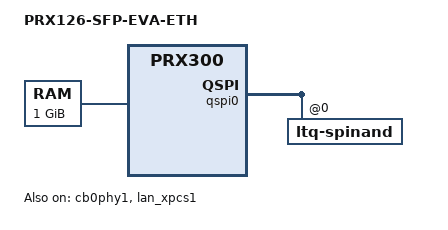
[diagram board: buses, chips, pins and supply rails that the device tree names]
/dts-v1/;
#include <dt-bindings/interrupt-controller/mips-gic.h>
#include <dt-bindings/clock/intel,prx300-clk.h>
#include <dt-bindings/pinctrl/intel,equilibrium.h>
#include "prx300.dtsi"
#include "prx126-sfp-eva.dtsi"

/ {
	model = "PRX126-SFP-EVA-ETH";
	compatible = "intel,prx126-sfp-eva-eth", "intel,prx126-eva", "intel,prx300";

	chosen {
		stdout-path = "serial0";
	};

	memory@0 {
		device_type = "memory";
		reg = <0x20000000 0x40000000>; /* 1024 MB */
	};
};

&qspi0 {
	status = "okay";
	ltq-spinand@0 {
		status = "okay";
	};
};

&cb0phy1 {
	intel,mode = <1>; /*0-pcie, 1-xpcs*/
	status = "okay";
};

&lan_xpcs1 {
	status = "okay";
	xpcs-mode = <0>; /* 0 - 10G_KR_MODE, 1 - 10G_XAUI_MODE, 2 - 1G_XAUI_MODE, 3 - 2P5G_GMII_MODE */
};
